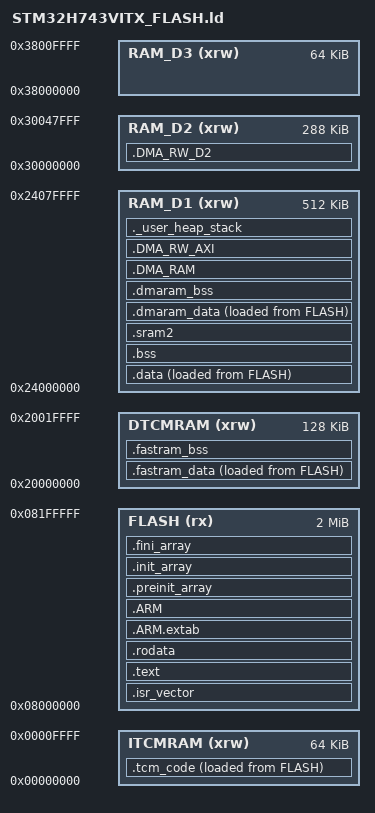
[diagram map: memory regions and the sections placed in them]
/*
******************************************************************************
**
**  File        : LinkerScript.ld
**
**  Author      : STM32CubeIDE
**
**  Abstract    : Linker script for STM32H7 series
**                2048Kbytes FLASH and 1056Kbytes RAM
**
**                Set heap size, stack size and stack location according
**                to application requirements.
**
**                Set memory bank area and size if external memory is used.
**
**  Target      : STMicroelectronics STM32
**
**  Distribution: The file is distributed as is, without any warranty
**                of any kind.
**
*****************************************************************************
** @attention
**
** Copyright (c) 2025 STMicroelectronics.
** All rights reserved.
**
** This software is licensed under terms that can be found in the LICENSE file
** in the root directory of this software component.
** If no LICENSE file comes with this software, it is provided AS-IS.
**
****************************************************************************
*/

/* Entry Point */
ENTRY(Reset_Handler)

/* Highest address of the user mode stack */
_estack = ORIGIN(RAM_D1) + LENGTH(RAM_D1);    /* end of RAM */
/* Generate a link error if heap and stack don't fit into RAM */
_Min_Heap_Size = 0x200;      /* required amount of heap  */
_Min_Stack_Size = 0x800; /* required amount of stack */

/* Specify the memory areas */
MEMORY
{
  FLASH (rx)     : ORIGIN = 0x08000000, LENGTH = 2048K
  DTCMRAM (xrw)  : ORIGIN = 0x20000000, LENGTH = 128K
  RAM_D1 (xrw)   : ORIGIN = 0x24000000, LENGTH = 512K
  RAM_D2 (xrw)   : ORIGIN = 0x30000000, LENGTH = 288K
  RAM_D3 (xrw)   : ORIGIN = 0x38000000, LENGTH = 64K
  ITCMRAM (xrw)  : ORIGIN = 0x00000000, LENGTH = 64K
}

/* Define output sections */
SECTIONS
{
  /* The startup code goes first into FLASH */
  .isr_vector :
  {
    . = ALIGN(4);
    KEEP(*(.isr_vector)) /* Startup code */
    . = ALIGN(4);
  } >FLASH

  /* The program code and other data goes into FLASH */
  .text :
  {
    . = ALIGN(4);
    *(.text)           /* .text sections (code) */
    *(.text*)          /* .text* sections (code) */
    *(.glue_7)         /* glue arm to thumb code */
    *(.glue_7t)        /* glue thumb to arm code */
    *(.eh_frame)

    KEEP (*(.init))
    KEEP (*(.fini))

    . = ALIGN(4);
    _etext = .;        /* define a global symbols at end of code */
  } >FLASH

  /* Constant data goes into FLASH */
  .rodata :
  {
    . = ALIGN(4);
    *(.rodata)         /* .rodata sections (constants, strings, etc.) */
    *(.rodata*)        /* .rodata* sections (constants, strings, etc.) */
    . = ALIGN(4);
  } >FLASH

  /* Critical program code goes into ITCM RAM */
  /* Copy specific fast-executing code to ITCM RAM */
  tcm_code = LOADADDR(.tcm_code);
  .tcm_code :
  {
    . = ALIGN(4);
    tcm_code_start = .;
    *(.tcm_code)
    *(.tcm_code*)
    . = ALIGN(4);
    tcm_code_end = .;
  } >ITCMRAM AT >FLASH

  .ARM.extab (READONLY) : /* The READONLY keyword is only supported in GCC11 and later, remove it if using GCC10 or earlier. */
  {
    *(.ARM.extab* .gnu.linkonce.armextab.*)
  } >FLASH
  .ARM (READONLY) : /* The READONLY keyword is only supported in GCC11 and later, remove it if using GCC10 or earlier. */
  {
    __exidx_start = .;
    *(.ARM.exidx*)
    __exidx_end = .;
  } >FLASH

  .preinit_array (READONLY) : /* The READONLY keyword is only supported in GCC11 and later, remove it if using GCC10 or earlier. */
  {
    PROVIDE_HIDDEN (__preinit_array_start = .);
    KEEP (*(.preinit_array*))
    PROVIDE_HIDDEN (__preinit_array_end = .);
  } >FLASH

  .init_array (READONLY) : /* The READONLY keyword is only supported in GCC11 and later, remove it if using GCC10 or earlier. */
  {
    PROVIDE_HIDDEN (__init_array_start = .);
    KEEP (*(SORT(.init_array.*)))
    KEEP (*(.init_array*))
    PROVIDE_HIDDEN (__init_array_end = .);
  } >FLASH

  .fini_array (READONLY) : /* The READONLY keyword is only supported in GCC11 and later, remove it if using GCC10 or earlier. */
  {
    PROVIDE_HIDDEN (__fini_array_start = .);
    KEEP (*(SORT(.fini_array.*)))
    KEEP (*(.fini_array*))
    PROVIDE_HIDDEN (__fini_array_end = .);
  } >FLASH

  /* used by the startup to initialize data */
  _sidata = LOADADDR(.data);

  /* Initialized data sections goes into RAM, load LMA copy after code */
  .data :
  {
    . = ALIGN(4);
    _sdata = .;        /* create a global symbol at data start */
    *(.data)           /* .data sections */
    *(.data*)          /* .data* sections */
    *(.RamFunc)        /* .RamFunc sections */
    *(.RamFunc*)       /* .RamFunc* sections */

    . = ALIGN(4);
    _edata = .;        /* define a global symbol at data end */
  } >RAM_D1 AT> FLASH

  /* Uninitialized data section */
  . = ALIGN(4);
  .bss :
  {
    /* This is used by the startup in order to initialize the .bss section */
    _sbss = .;         /* define a global symbol at bss start */
    __bss_start__ = _sbss;
    *(.bss)
    *(.bss*)
    *(COMMON)

    . = ALIGN(4);
    _ebss = .;         /* define a global symbol at bss end */
    __bss_end__ = _ebss;
  } >RAM_D1
  
  /* Uninitialized data section */
  . = ALIGN(4);
  .sram2 (NOLOAD) :
  {
    /* This is used by the startup in order to initialize the .sram2 secion */
    _ssram2 = .;         /* define a global symbol at sram2 start */
    __sram2_start__ = _ssram2;
    *(.sram2)
    *(SORT_BY_ALIGNMENT(.sram2*))

    . = ALIGN(4);
    _esram2 = .;         /* define a global symbol at sram2 end */
    __sram2_end__ = _esram2;
  } >RAM_D1

  /* used during startup to initialized fastram_data */
  _sfastram_idata = LOADADDR(.fastram_data);

  /* Initialized FAST_DATA section for unsuspecting developers */
  .fastram_data :
  {
    . = ALIGN(4);
    _sfastram_data = .;        /* create a global symbol at data start */
    *(.fastram_data)           /* .data sections */
    *(.fastram_data*)          /* .data* sections */

    . = ALIGN(4);
    _efastram_data = .;        /* define a global symbol at data end */
  } >DTCMRAM AT >FLASH

  . = ALIGN(4);
  .fastram_bss (NOLOAD) :
  {
    _sfastram_bss = .;
    __fastram_bss_start__ = _sfastram_bss;
    *(.fastram_bss)
    *(SORT_BY_ALIGNMENT(.fastram_bss*))

    . = ALIGN(4);
    _efastram_bss = .;
    __fastram_bss_end__ = _efastram_bss;
  } >DTCMRAM

  /* used during startup to initialized dmaram_data */
  _sdmaram_idata = LOADADDR(.dmaram_data);

  . = ALIGN(32);
  .dmaram_data :
  {
    PROVIDE(dmaram_start = .);
    _sdmaram = .;
    _dmaram_start__ = _sdmaram;
    _sdmaram_data = .;        /* create a global symbol at data start */
    *(.dmaram_data)           /* .data sections */
    *(.dmaram_data*)          /* .data* sections */
    . = ALIGN(32);
    _edmaram_data = .;        /* define a global symbol at data end */
  } >RAM_D1 AT >FLASH

  . = ALIGN(32);
  .dmaram_bss (NOLOAD) :
  {
    _sdmaram_bss = .;
    __dmaram_bss_start__ = _sdmaram_bss;
    *(.dmaram_bss)
    *(SORT_BY_ALIGNMENT(.dmaram_bss*))
    . = ALIGN(32);
    _edmaram_bss = .;
    __dmaram_bss_end__ = _edmaram_bss;
  } >RAM_D1

  . = ALIGN(32);
  .DMA_RAM (NOLOAD) :
  {
    KEEP(*(.DMA_RAM))
    PROVIDE(dmaram_end = .);
    _edmaram = .;
    _dmaram_end__ = _edmaram;
  } >RAM_D1

  .DMA_RW_D2 (NOLOAD) :
  {
    . = ALIGN(32);
    PROVIDE(dmarw_start = .);
    _sdmarw = .;
    _dmarw_start__ = _sdmarw;
    KEEP(*(.DMA_RW))
    PROVIDE(dmarw_end = .);
    _edmarw = .;
    _dmarw_end__ = _edmarw;
  } >RAM_D2

  .DMA_RW_AXI (NOLOAD) :
  {
    . = ALIGN(32);
    PROVIDE(dmarwaxi_start = .);
    _sdmarwaxi = .;
    _dmarwaxi_start__ = _sdmarwaxi;
    KEEP(*(.DMA_RW_AXI))
    PROVIDE(dmarwaxi_end = .);
    _edmarwaxi = .;
    _dmarwaxi_end__ = _edmarwaxi;
  } >RAM_D1

  /* User_heap_stack section, used to check that there is enough RAM left */
  ._user_heap_stack :
  {
    . = ALIGN(8);
    PROVIDE ( end = . );
    PROVIDE ( _end = . );
    . = . + _Min_Heap_Size;
    . = . + _Min_Stack_Size;
    . = ALIGN(8);
  } >RAM_D1

  /* Remove information from the standard libraries */
  /DISCARD/ :
  {
    libc.a ( * )
    libm.a ( * )
    libgcc.a ( * )
  }

  .ARM.attributes 0 : { *(.ARM.attributes) }
}


